VERSION ""

NS_ :

BS_:

BU_: AEC_ENGINE_01 AEC_TRANSMISSION_01

BO_ 2364540416 BrakeStatus: 3 AEC_TRANSMISSION_01
 SG_ Brake_Pressure : 0|16@1+ (0.01,0) [0|250] "bar" Vector__XXX
 SG_ Brake_Applied : 16|1@1+ (1,0) [0|1] "" Vector__XXX

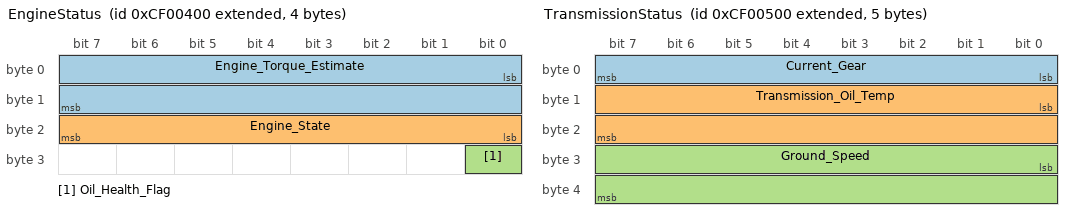
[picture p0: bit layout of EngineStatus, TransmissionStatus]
BO_ 2364539904 EngineStatus: 4 AEC_ENGINE_01
 SG_ Engine_Torque_Estimate : 0|16@1+ (0.01,0) [0|100] "%" Vector__XXX
 SG_ Engine_State : 16|8@1+ (1,0) [0|15] "" Vector__XXX
 SG_ Oil_Health_Flag : 24|1@1+ (1,0) [0|1] "" Vector__XXX

BO_ 2364540160 TransmissionStatus: 5 AEC_TRANSMISSION_01
 SG_ Current_Gear : 0|8@1+ (1,0) [0|24] "" Vector__XXX
 SG_ Transmission_Oil_Temp : 8|16@1- (0.1,0) [-40|150] "degC" Vector__XXX
 SG_ Ground_Speed : 24|16@1+ (0.01,0) [0|6000] "Hz" Vector__XXX
